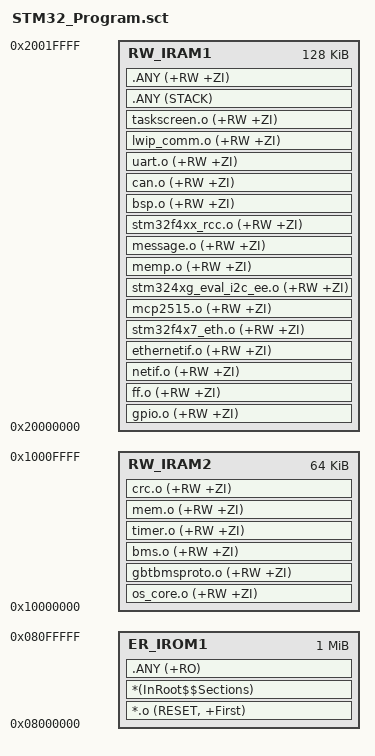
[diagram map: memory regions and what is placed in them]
; *************************************************************
; *** Scatter-Loading Description File generated by uVision ***
; *************************************************************

LR_IROM1 0x08000000 0x00100000  {    ; load region size_region
   ER_IROM1 0x08000000 0x00100000  {  ; load address = execution address
;LR_IROM1 0x08020000 0x00100000  {    ; load region size_region
;   ER_IROM1 0x08020000 0x00100000  {  ; load address = execution address   
;LR_IROM1 0x08080000 0x00100000  {    ; load region size_region
;  ER_IROM1 0x08080000 0x00100000  {  ; load address = execution address
   *.o (RESET, +First)
   *(InRoot$$Sections)
   .ANY (+RO)
  }
  RW_IRAM1 0x20000000 0x00020000  {  ; RW data  

  gpio.o (+RW +ZI)
  ff.o (+RW +ZI)
  netif.o (+RW +ZI)
  ethernetif.o (+RW +ZI)
  stm32f4x7_eth.o (+RW +ZI)
  mcp2515.o (+RW +ZI)
  stm324xg_eval_i2c_ee.o (+RW +ZI)
  memp.o (+RW +ZI)
 ; mem.o (+RW +ZI)
 ; memory.o (+RW +ZI)
  message.o  (+RW +ZI)
  stm32f4xx_rcc.o  (+RW +ZI)
  bsp.o (+RW +ZI)
  can.o  (+RW +ZI)
  uart.o (+RW +ZI)   
  lwip_comm.o  (+RW +ZI)
  taskscreen.o  (+RW +ZI)
  .ANY (STACK)  
   .ANY (+RW +ZI)
  }
  RW_IRAM2 0x10000000 0x00010000  {
  
 os_core.o (+RW +ZI)	
; main.o  (+RW +ZI)
; chgdata.o  (+RW +ZI)
; billingunit.o  (+RW +ZI)
; che_dian.o  (+RW +ZI)
; taskscreen.o  (+RW +ZI)
; powersplitt.o  (+RW +ZI)
; cdmodel.o  (+RW +ZI)
; taskdcmeter.o  (+RW +ZI)
 gbtbmsproto.o  (+RW +ZI)
; message.o  (+RW +ZI)
; can.o  (+RW +ZI)
; uart.o (+RW +ZI) 
; adebug.o (+RW +ZI) 
 bms.o	(+RW +ZI) 
 timer.o (+RW +ZI) 
; memory.o (+RW +ZI)  
; memp.o (+RW +ZI)
 mem.o (+RW +ZI)
;sys_arch.o (+RW +ZI)
crc.o (+RW +ZI)
; .ANY (STACK)
; .ANY (HEAP) 
; .ANY (+RW +ZI)  
  }
 ; UCOS_ii_IARM 0x10000000 0x00002000{
;	
 ; }
}

